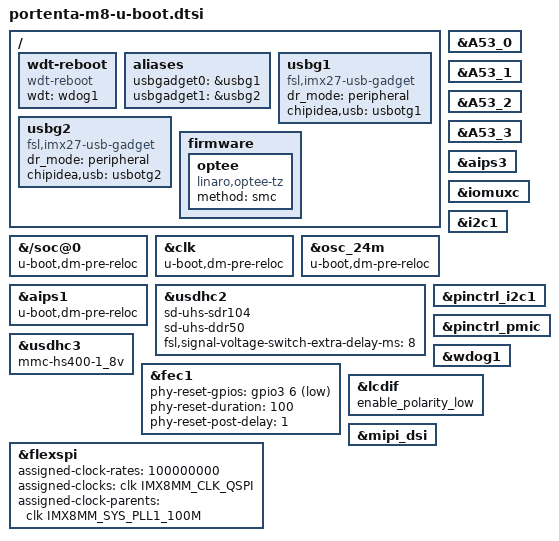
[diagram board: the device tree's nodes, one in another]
// SPDX-License-Identifier: GPL-2.0+
/*
 * Copyright 2019 NXP
 */

/ {
	wdt-reboot {
		compatible = "wdt-reboot";
		wdt = <&wdog1>;
		u-boot,dm-spl;
	};

	aliases {
		usbgadget0 = &usbg1;
		usbgadget1 = &usbg2;
	};

	usbg1: usbg1 {
		compatible = "fsl,imx27-usb-gadget";
		dr_mode = "peripheral";
		chipidea,usb = <&usbotg1>;
		status = "okay";
	};

	usbg2: usbg2 {
		compatible = "fsl,imx27-usb-gadget";
		dr_mode = "peripheral";
		chipidea,usb = <&usbotg2>;
		status = "okay";
	};

	firmware {
		optee {
			compatible = "linaro,optee-tz";
			method = "smc";
		};
	};
};

&{/soc@0} {
	u-boot,dm-pre-reloc;
	u-boot,dm-spl;
};

&A53_0 {
	/delete-property/ cpu-idle-states;
};

&A53_1 {
	/delete-property/ cpu-idle-states;
};

&A53_2 {
	/delete-property/ cpu-idle-states;
};

&A53_3 {
	/delete-property/ cpu-idle-states;
};

&clk {
	u-boot,dm-spl;
	u-boot,dm-pre-reloc;
	/delete-property/ assigned-clocks;
	/delete-property/ assigned-clock-parents;
	/delete-property/ assigned-clock-rates;
};

&osc_24m {
	u-boot,dm-spl;
	u-boot,dm-pre-reloc;
};

&aips1 {
	u-boot,dm-spl;
	u-boot,dm-pre-reloc;
};

&aips3 {
	u-boot,dm-spl;
};

&iomuxc {
	u-boot,dm-spl;
};

&usdhc2 {
	u-boot,dm-spl;
	sd-uhs-sdr104;
	sd-uhs-ddr50;
	fsl,signal-voltage-switch-extra-delay-ms = <8>;
};

&usdhc3 {
	u-boot,dm-spl;
	mmc-hs400-1_8v;
};

&i2c1 {
	u-boot,dm-spl;
};

&pinctrl_i2c1 {
	u-boot,dm-spl;
};

&pinctrl_pmic {
	u-boot,dm-spl;
};

&fec1 {
	phy-reset-gpios = <&gpio3 6 GPIO_ACTIVE_LOW>;
	phy-reset-duration = <100>;
	phy-reset-post-delay = <1>;
};

&wdog1 {
	u-boot,dm-spl;
};

&flexspi {
	assigned-clock-rates = <100000000>;
	assigned-clocks = <&clk IMX8MM_CLK_QSPI>;
	assigned-clock-parents = <&clk IMX8MM_SYS_PLL1_100M>;
};

&lcdif {
	enable_polarity_low;
	/delete-property/ assigned-clocks;
	/delete-property/ assigned-clock-parents;
	/delete-property/ assigned-clock-rates;
};

&mipi_dsi {
	/delete-property/ assigned-clocks;
	/delete-property/ assigned-clock-parents;
	/delete-property/ assigned-clock-rates;
};
